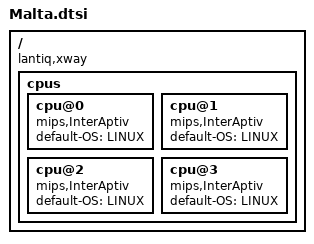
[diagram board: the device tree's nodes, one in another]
/ {
	#address-cells = <1>;
	#size-cells = <1>;
	compatible = "lantiq,xway", "lantiq,grx500";

	cpus {
		cpu@0 {
			compatible = "mips,InterAptiv";
			default-OS = "LINUX";
		};
		cpu@1 {
			compatible = "mips,InterAptiv";
			default-OS = "LINUX";
		};
		cpu@2 {
			compatible = "mips,InterAptiv";
			default-OS = "LINUX";
		};
		cpu@3 {
			compatible = "mips,InterAptiv";
			default-OS = "LINUX";
		};
	};
};
